# A31T51x register map
Vendor: ABOV Semiconductor Co., Ltd.; File version: 1.0
ARM Cortex-M0 32-bit MCU, CPU clock up to 48 MHz, etc.
CPU: CM0PLUS r0p1, little endian, no MPU, no FPU, VTOR, 2 interrupt priority bits
Registers are 32-bit, read-write, reset 0x0 unless marked. A register's access mark holds for its fields unless they carry their own. Offsets are from the block's base; lines under a group give offsets from that group; [hi:lo] are bit positions; {n}, {i} and the like mark numbered series; 'fields as' and 'values as' point back to an identical list; <NAME> marks a mode.

## Memory map
0x40000000 SCU size 0x100 — System Control Unit
0x40000200 WDT size 0x100 — WATCH-DOG TIMER
{0x40000400+0x10*n} DMA{n} size 0x10 (n=0..7)
0x40000600 FRT size 0x100 — Free Run Timer
0x40000900 RTCC size 0x100 — Real-time clock
0x40001000 USART10 size 0x100
0x40001100 USART11 size 0x100
0x40001200 USART12 size 0x100
{0x40003000+0x40*n} TIMER{n} size 0x40 (n=0..11)
0x40003800 TOUCH0 size 0x200 — Touch Sensor
0x40003A00 TOUCH1 size 0x200
0x40004000 HSICMU size 0x20 — HIGH-SPEED INTERNAL OSC CLOCK MANAGEMENT UNIT
0x40008000 UART0 size 0x100
0x40008100 UART1 size 0x100
0x40008200 UART2 size 0x100
0x40008300 UART3 size 0x100
0x40008400 UART4 size 0x100
0x40009000 SPI size 0x100 — Serial Peripheral Interface Bus
0x4000A000 I2C0 size 0x100
0x4000A100 I2C1 size 0x100
0x4000A200 I2C2 size 0x100
0x4000B380 CMP0 size 0x10
0x4000B390 CMP1 size 0x10
0x4000F000 CHIPCONFIG size 0x10 — Chip Configuration Data
0x4000F020 DBGMCU size 0x10 — Debug MCU Control Register
0x40080000 CFMC size 0x1000 — CODE FLASH MEMORY CONTROLLER
0x40081000 DFMC size 0x1000 — DATA FLASH MEMORY CONTROLLER
0x40082000 CRC size 0x1000 — Cyclic Redundancy Check calculation module
0x40090000 PA size 0x100
0x40090100 PB size 0x100
0x40090200 PC size 0x100
0x40090300 PD size 0x100
0x40090400 PE size 0x100
0x40090F0C PORTRSTDBCR size 0xF — General Port Reset Debounce Enable
0x40090FF0 PORTEN size 0xF — General Port Access Enable
0x40092000 ADC size 0x100 — 12-BIT A/D CONVERTER
0x50000400 DMA size 0x10 — Direct Memory Access Control 0
0x50001000 USART size 0x100 — USART 10 (UART + SPI)
0x50003000 TIMER size 0x40 — TIMER COUNTER 0
0x50008000 UART size 0x100 — Universal Asynchronous Receiver/Transmitter 0
0x5000A000 I2C size 0x100 — Inter-Integrated Circuit
0x5000B380 CMP size 0x10 — Comparator
0x50090000 PCU size 0x100 — General Port

## Interrupts
0 LVI_TOUCH0 (SCU, TOUCH0)
1 SYSCLKFAIL_TOUCH1 (SCU, TOUCH1)
2 HSEFAIL_DFMC (SCU, DFMC)
3 LSEFAIL_RTCC (SCU, RTCC)
4 WDT
5 FRT_TIMER10 (TIMER10, FRT)
6 CFMC_TIMER11 (CFMC, TIMER11)
7 TIMER0
8 TIMER1
9 TIMER2
10 TIMER3
11 GPIOAB (PA, PB)
12 GPIOCD (PC, PD)
13 GPIOE (PE)
14 TIMER4
15 TIMER5
16 USART10
17 USART11
18 USART12
19 I2C0
20 UART0
21 UART1
22 ADC
23 CRC_UART2 (UART2, CRC)
24 CMP0_SPI0 (SPI, CMP0)
25 CMP1
26 I2C1
27 I2C2
28 TIMER6
29 TIMER7
30 TIMER8_UART3 (TIMER8, UART3)
31 TIMER9_UART4 (TIMER9, UART4)

## CHIPCONFIG — Chip Configuration Data
Base 0x4000F000
0x00 VENDID ro reset 0x41424F56 — Vendor identification bits
0x04 CHIPID ro reset 0x54315180 — Chip ID bits
0x08 REVNO 8-bit ro — Chip revision number

## PCU — General Port
Base 0x50090000
Same registers: PA 0x40090000, PB 0x40090100, PC 0x40090200, PD 0x40090300, PE 0x40090400
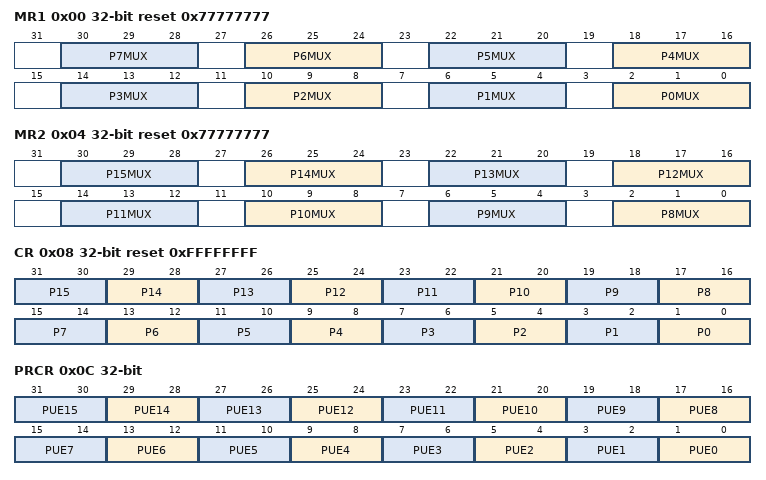
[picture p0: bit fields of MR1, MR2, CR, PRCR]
0x00 MR1 reset 0x77777777 — Port n MUX1 Selection Register
  [4n+2:4n] P{n}MUX (n=0..7) — Pin {n} Mode Selection bits
0x04 MR2 reset 0x77777777 — Port n MUX2 Selection Register
  [4n-30:4n-32] P{n}MUX (n=8..15) — Pin {n} Mode Selection bits
0x08 CR reset 0xFFFFFFFF — Port n Type Selection Register
  [2n+1:2n] P{n} (n=0..15) — Pin {n} Type Selection bit
0x0C PRCR — Port n Pull-up/down Selection Register
  [2n+1:2n] PUE{n} (n=0..15) — Pin {n} Pull-up/down Selection bits
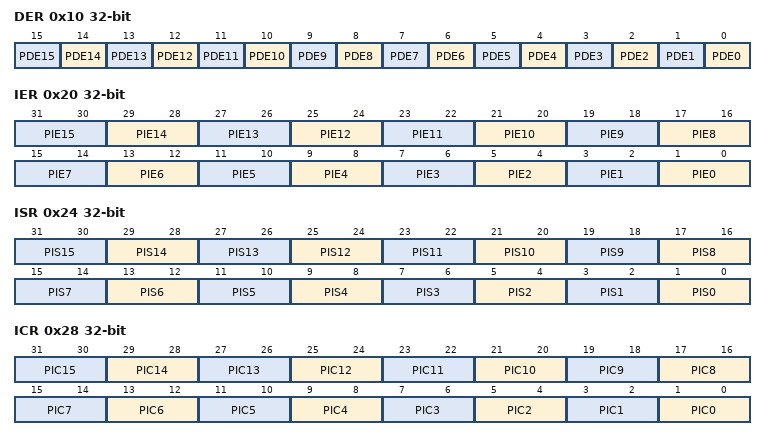
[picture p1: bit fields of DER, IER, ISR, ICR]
0x10 DER — Port n Debounce Enable Register
  [n] PDE{n} (n=0..15) — Pin {n} Debounce Enable bits
0x20 IER — Port n Interrupt Enable Register
  [2n+1:2n] PIE{n} (n=0..15) — Pin {n} Interrupt Enable bit
0x24 ISR — Port n Interrupt Status Register
  [2n+1:2n] PIS{n} (n=0..15) — Pin {n} Interrupt Status bit
0x28 ICR — Port n Interrupt Control Register
  [2n+1:2n] PIC{n} (n=0..15) — Pin {n} Interrupt Control bit
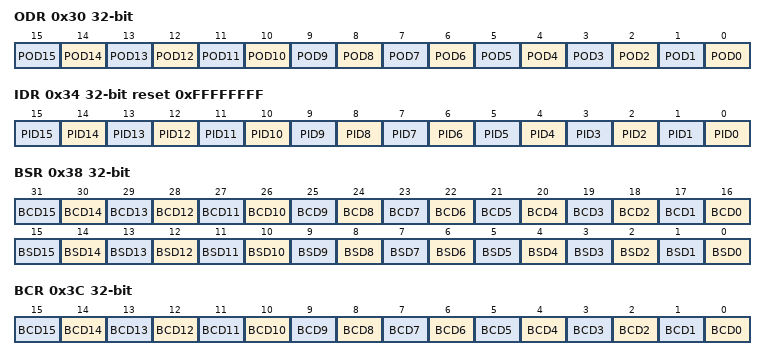
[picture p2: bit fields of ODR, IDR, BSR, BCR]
0x30 ODR — Port n Output Data Register
  [n] POD{n} (n=0..15) — Pin {n} Output data bit
0x34 IDR ro reset 0xFFFFFFFF — Port n Input Data Register
  [n] PID{n} rw (n=0..15) — Pin {n} Input data bit
0x38 BSR wo — Port n Bit Set/Clear Register
  [n+16] BCD{n} (n=0..15) — Port {n} Bit Clear bits
  [n] BSD{n} (n=0..15) — Port {n} Bit Set bits
0x3C BCR wo — Port n Bit Reset Register
  [n] BCD{n} (n=0..15) — Port {n} Bit Clear bits
